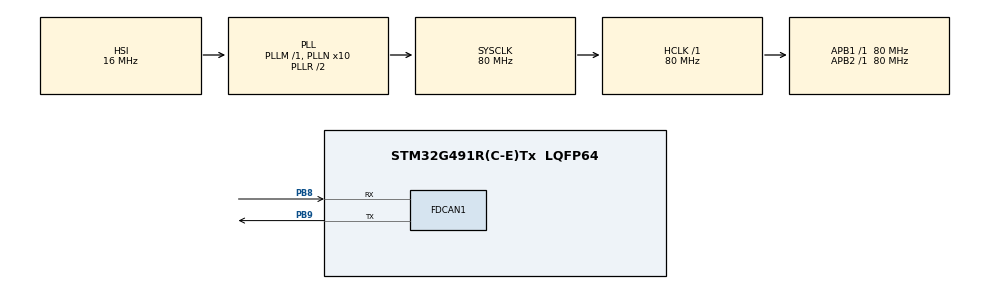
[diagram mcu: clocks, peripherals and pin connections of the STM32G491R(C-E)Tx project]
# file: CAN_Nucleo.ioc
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FDCAN1.CalculateBaudRateNominal=500000
FDCAN1.CalculateTimeBitNominal=2000
FDCAN1.CalculateTimeQuantumNominal=50.0
FDCAN1.DataPrescaler=8
FDCAN1.DataSyncJumpWidth=5
FDCAN1.DataTimeSeg1=14
FDCAN1.DataTimeSeg2=5
FDCAN1.NominalPrescaler=4
FDCAN1.NominalSyncJumpWidth=5
FDCAN1.NominalTimeSeg1=34
FDCAN1.NominalTimeSeg2=5
FDCAN1.StdFiltersNbr=1
Mcu.Family=STM32G4
Mcu.Name=STM32G491R(C-E)Tx
Mcu.Package=LQFP64
NVIC.FDCAN1_IT0_IRQn=true\:1\:0\:true\:false\:true\:true\:true\:true
NVIC.PriorityGroup=NVIC_PRIORITYGROUP_4
PA13.Mode=Serial_Wire
PA13.Signal=SYS_JTMS-SWDIO
PA14.Mode=Serial_Wire
PA14.Signal=SYS_JTCK-SWCLK
PB8-BOOT0.GPIO_Speed=GPIO_SPEED_FREQ_VERY_HIGH
PB8-BOOT0.Mode=FDCAN_Activate
PB8-BOOT0.Signal=FDCAN1_RX
PB9.GPIO_Speed=GPIO_SPEED_FREQ_VERY_HIGH
PB9.Mode=FDCAN_Activate
PB9.Signal=FDCAN1_TX
PF0-OSC_IN.Mode=HSE-External-Oscillator
PF0-OSC_IN.Signal=RCC_OSC_IN
PF1-OSC_OUT.Mode=HSE-External-Oscillator
PF1-OSC_OUT.Signal=RCC_OSC_OUT
ProjectManager.HeapSize=0x200
ProjectManager.StackSize=0x400
ProjectManager.TargetToolchain=STM32CubeIDE
RCC.ADC12Freq_Value=80000000
RCC.ADC345Freq_Value=80000000
RCC.AHBFreq_Value=80000000
RCC.APB1Freq_Value=80000000
RCC.APB1TimFreq_Value=80000000
RCC.APB2Freq_Value=80000000
RCC.APB2TimFreq_Value=80000000
RCC.CortexFreq_Value=80000000
RCC.EXTERNAL_CLOCK_VALUE=12288000
RCC.HCLKFreq_Value=80000000
RCC.HSE_VALUE=8000000
RCC.HSI48_VALUE=48000000
RCC.HSI_VALUE=16000000
RCC.LSE_VALUE=32768
RCC.PLLN=10
RCC.SYSCLKFreq_VALUE=80000000
RCC.SYSCLKSource=RCC_SYSCLKSOURCE_PLLCLK
RCC.USBFreq_Value=48000000
RCC.VCOOutputFreq_Value=160000000
VP_SYS_VS_DBSignals.Mode=DisableDeadBatterySignals
board=custom

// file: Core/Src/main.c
/* USER CODE BEGIN Header */
/**
  ******************************************************************************
  * @file           : main.c
  * @brief          : Main program body
  ******************************************************************************
  * @attention
  *
  * Copyright (c) 2025 STMicroelectronics.
  * All rights reserved.
  *
  * This software is licensed under terms that can be found in the LICENSE file
  * in the root directory of this software component.
  * If no LICENSE file comes with this software, it is provided AS-IS.
  *
  ******************************************************************************
  */
/* USER CODE END Header */
#include "main.h"
#include "string.h"

FDCAN_HandleTypeDef hfdcan1;

void SystemClock_Config(void);
static void MX_GPIO_Init(void);
static void MX_FDCAN1_Init(void);

/* USER CODE BEGIN 0 */

FDCAN_TxHeaderTypeDef TxHeader;
//FDCAN_RxHeaderTypeDef RxHeader;

uint8_t TxData[8];
//char TxData[]="IGVC!";
uint8_t RxData[8];
//uint8_t datatobesent[1024];
//int k=0;

//uint32_t TxMailbox;

/* USER CODE END 0 */

int main(void)
{

  /* MCU Configuration--------------------------------------------------------*/

  /* Reset of all peripherals, Initializes the Flash interface and the Systick. */
  HAL_Init();

  /* Configure the system clock */
  SystemClock_Config();

  /* Initialize all configured peripherals */
  MX_GPIO_Init();
  MX_FDCAN1_Init();
  /* USER CODE BEGIN 2 */

  if(HAL_FDCAN_Start(&hfdcan1)!= HAL_OK)Error_Handler();

    TxHeader.BitRateSwitch = FDCAN_BRS_OFF;
    TxHeader.DataLength=FDCAN_DLC_BYTES_8;
    TxHeader.ErrorStateIndicator=FDCAN_ESI_ACTIVE;
    TxHeader.FDFormat=FDCAN_CLASSIC_CAN;
    TxHeader.IdType=FDCAN_STANDARD_ID;
    TxHeader.Identifier=0x123;
    TxHeader.MessageMarker=0;
    TxHeader.TxEventFifoControl=FDCAN_NO_TX_EVENTS;
    TxHeader.TxFrameType=FDCAN_DATA_FRAME;

  for(int i = 0;i<8;i++)
	  TxData[i]=i+1;

//strcpy(datatobesent,"NeverGonnaGiveYouUpNeverGonnaLetYouDownNeverGonnaRunAroundAndDesertYou");
  /* USER CODE END 2 */

  /* Infinite loop */
  /* USER CODE BEGIN WHILE */
  while (1)
  {

	  for(int i = 0;i<8;i++){
		  TxData[i]=(TxData[i]+1)%8;
	  }
//	  for(int i =0;i<8;i++){
//		  TxData[i]=datatobesent[k];
//		  k=(k+1)%(strlen(datatobesent));
//	  }

	  if(HAL_FDCAN_AddMessageToTxFifoQ(&hfdcan1, &TxHeader,TxData)!= HAL_OK)Error_Handler();
	  HAL_Delay(500);

		  /* USER CODE END WHILE */

  }
}

void SystemClock_Config(void)
{
  RCC_OscInitTypeDef RCC_OscInitStruct = {0};
  RCC_ClkInitTypeDef RCC_ClkInitStruct = {0};

  /** Configure the main internal regulator output voltage
  */
  HAL_PWREx_ControlVoltageScaling(PWR_REGULATOR_VOLTAGE_SCALE1);

  /** Initializes the RCC Oscillators according to the specified parameters
  * in the RCC_OscInitTypeDef structure.
  */
  RCC_OscInitStruct.OscillatorType = RCC_OSCILLATORTYPE_HSI;
  RCC_OscInitStruct.HSIState = RCC_HSI_ON;
  RCC_OscInitStruct.HSICalibrationValue = RCC_HSICALIBRATION_DEFAULT;
  RCC_OscInitStruct.PLL.PLLState = RCC_PLL_ON;
  RCC_OscInitStruct.PLL.PLLSource = RCC_PLLSOURCE_HSI;
  RCC_OscInitStruct.PLL.PLLM = RCC_PLLM_DIV1;
  RCC_OscInitStruct.PLL.PLLN = 10;
  RCC_OscInitStruct.PLL.PLLP = RCC_PLLP_DIV2;
  RCC_OscInitStruct.PLL.PLLQ = RCC_PLLQ_DIV2;
  RCC_OscInitStruct.PLL.PLLR = RCC_PLLR_DIV2;
  if (HAL_RCC_OscConfig(&RCC_OscInitStruct) != HAL_OK)
  {
    Error_Handler();
  }

  /** Initializes the CPU, AHB and APB buses clocks
  */
  RCC_ClkInitStruct.ClockType = RCC_CLOCKTYPE_HCLK|RCC_CLOCKTYPE_SYSCLK
                              |RCC_CLOCKTYPE_PCLK1|RCC_CLOCKTYPE_PCLK2;
  RCC_ClkInitStruct.SYSCLKSource = RCC_SYSCLKSOURCE_PLLCLK;
  RCC_ClkInitStruct.AHBCLKDivider = RCC_SYSCLK_DIV1;
  RCC_ClkInitStruct.APB1CLKDivider = RCC_HCLK_DIV1;
  RCC_ClkInitStruct.APB2CLKDivider = RCC_HCLK_DIV1;

  if (HAL_RCC_ClockConfig(&RCC_ClkInitStruct, FLASH_LATENCY_2) != HAL_OK)
  {
    Error_Handler();
  }
}

static void MX_FDCAN1_Init(void)
{

  hfdcan1.Instance = FDCAN1;
  hfdcan1.Init.ClockDivider = FDCAN_CLOCK_DIV1;
  hfdcan1.Init.FrameFormat = FDCAN_FRAME_CLASSIC;
  hfdcan1.Init.Mode = FDCAN_MODE_NORMAL;
  hfdcan1.Init.AutoRetransmission = DISABLE;
  hfdcan1.Init.TransmitPause = DISABLE;
  hfdcan1.Init.ProtocolException = DISABLE;
  hfdcan1.Init.NominalPrescaler = 4;
  hfdcan1.Init.NominalSyncJumpWidth = 5;
  hfdcan1.Init.NominalTimeSeg1 = 34;
  hfdcan1.Init.NominalTimeSeg2 = 5;
  hfdcan1.Init.DataPrescaler = 8;
  hfdcan1.Init.DataSyncJumpWidth = 5;
  hfdcan1.Init.DataTimeSeg1 = 14;
  hfdcan1.Init.DataTimeSeg2 = 5;
  hfdcan1.Init.StdFiltersNbr = 1;
  hfdcan1.Init.ExtFiltersNbr = 0;
  hfdcan1.Init.TxFifoQueueMode = FDCAN_TX_FIFO_OPERATION;
  if (HAL_FDCAN_Init(&hfdcan1) != HAL_OK)
  {
    Error_Handler();
  }

}

static void MX_GPIO_Init(void)
{

  /* GPIO Ports Clock Enable */
  __HAL_RCC_GPIOF_CLK_ENABLE();
  __HAL_RCC_GPIOA_CLK_ENABLE();
  __HAL_RCC_GPIOB_CLK_ENABLE();

}

void Error_Handler(void)
{
  __disable_irq();
  while (1)
  {
  }
}
